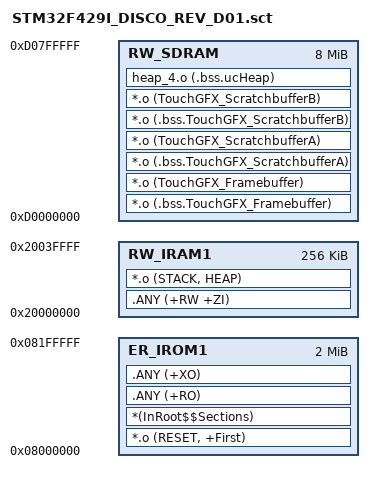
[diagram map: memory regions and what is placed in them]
; *************************************************************
; *** Scatter-Loading Description File generated by uVision ***
; *************************************************************

LR_IROM1 0x08000000 0x00200000  {    ; load region size_region
  ER_IROM1 0x08000000 0x00200000  {  ; load address = execution address
   *.o (RESET, +First)
   *(InRoot$$Sections)
   .ANY (+RO)
   .ANY (+XO)
  }
  RW_IRAM1 0x20000000 0x00040000  {  ; RW data - 256KB internal RAM
   .ANY (+RW +ZI)
   *.o (STACK, HEAP)
  }
  RW_SDRAM 0xD0000000 0x00800000  {  ; External SDRAM - 8MB  
   *.o (.bss.TouchGFX_Framebuffer)
   *.o (TouchGFX_Framebuffer)
   *.o (.bss.TouchGFX_ScratchbufferA)
   *.o (TouchGFX_ScratchbufferA)
   *.o (.bss.TouchGFX_ScratchbufferB)
   *.o (TouchGFX_ScratchbufferB)
   heap_4.o (.bss.ucHeap)
  }
}

